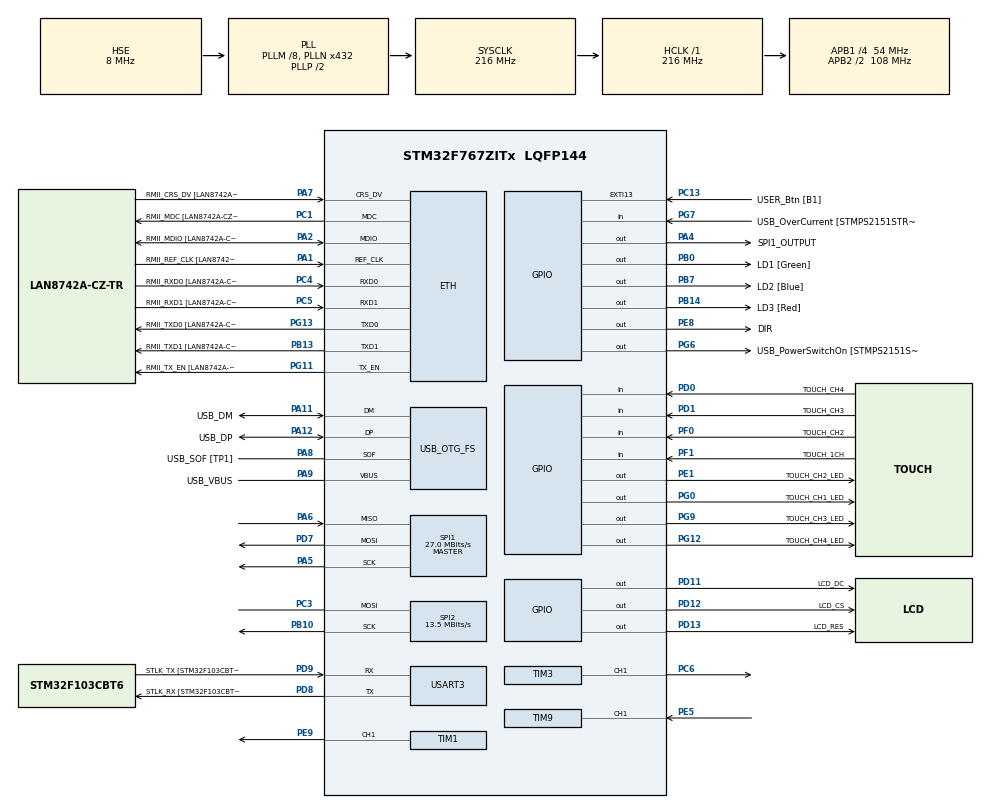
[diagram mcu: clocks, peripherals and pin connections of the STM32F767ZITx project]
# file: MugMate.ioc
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Dma.Request0=USART3_RX
Dma.Request1=SPI2_TX
Dma.SPI2_TX.1.Direction=DMA_MEMORY_TO_PERIPH
Dma.SPI2_TX.1.FIFOMode=DMA_FIFOMODE_DISABLE
Dma.SPI2_TX.1.Instance=DMA1_Stream4
Dma.SPI2_TX.1.MemDataAlignment=DMA_MDATAALIGN_BYTE
Dma.SPI2_TX.1.MemInc=DMA_MINC_ENABLE
Dma.SPI2_TX.1.Mode=DMA_NORMAL
Dma.SPI2_TX.1.PeriphDataAlignment=DMA_PDATAALIGN_BYTE
Dma.SPI2_TX.1.PeriphInc=DMA_PINC_DISABLE
Dma.SPI2_TX.1.Priority=DMA_PRIORITY_LOW
Dma.USART3_RX.0.Direction=DMA_PERIPH_TO_MEMORY
Dma.USART3_RX.0.FIFOMode=DMA_FIFOMODE_DISABLE
Dma.USART3_RX.0.Instance=DMA1_Stream1
Dma.USART3_RX.0.MemDataAlignment=DMA_MDATAALIGN_BYTE
Dma.USART3_RX.0.MemInc=DMA_MINC_ENABLE
Dma.USART3_RX.0.Mode=DMA_CIRCULAR
Dma.USART3_RX.0.PeriphDataAlignment=DMA_PDATAALIGN_BYTE
Dma.USART3_RX.0.PeriphInc=DMA_PINC_DISABLE
Dma.USART3_RX.0.Priority=DMA_PRIORITY_MEDIUM
ETH.MediaInterface=HAL_ETH_RMII_MODE
ETH.PHY_Name=LAN8742A_PHY_ADDRESS
ETH.PHY_Value=0
ETH.PhyAddress=0
Mcu.Family=STM32F7
Mcu.Name=STM32F767ZITx
Mcu.Package=LQFP144
NVIC.DMA1_Stream1_IRQn=true\:0\:0\:false\:false\:true\:false\:true\:true
NVIC.DMA1_Stream4_IRQn=true\:0\:0\:false\:false\:true\:false\:true\:true
NVIC.PriorityGroup=NVIC_PRIORITYGROUP_4
NVIC.TIM1_BRK_TIM9_IRQn=true\:0\:0\:false\:false\:true\:true\:true\:true
PA1.GPIO_Label=RMII_REF_CLK [LAN8742A-CZ-TR_REFCLK0]
PA1.Mode=RMII
PA1.Signal=ETH_REF_CLK
PA10.GPIO_Label=USB_ID
PA10.Signal=USB_OTG_FS_ID
PA11.GPIO_Label=USB_DM
PA11.Mode=Device_Only
PA11.Signal=USB_OTG_FS_DM
PA12.GPIO_Label=USB_DP
PA12.Mode=Device_Only
PA12.Signal=USB_OTG_FS_DP
PA13.GPIO_Label=TMS
PA13.Mode=Serial_Wire
PA13.Signal=SYS_JTMS-SWDIO
PA14.GPIO_Label=TCK
PA14.Mode=Serial_Wire
PA14.Signal=SYS_JTCK-SWCLK
PA2.GPIO_Label=RMII_MDIO [LAN8742A-CZ-TR_MDIO]
PA2.Mode=RMII
PA2.Signal=ETH_MDIO
PA4.GPIO_Label=SPI1_OUTPUT
PA4.PinState=GPIO_PIN_SET
PA4.Signal=GPIO_Output
PA5.Mode=Full_Duplex_Master
PA5.Signal=SPI1_SCK
PA6.Mode=Full_Duplex_Master
PA6.Signal=SPI1_MISO
PA7.GPIO_Label=RMII_CRS_DV [LAN8742A-CZ-TR_CRS_DV]
PA7.Mode=RMII
PA7.Signal=ETH_CRS_DV
PA8.GPIO_Label=USB_SOF [TP1]
PA8.Mode=Activate_SOF_FS
PA8.Signal=USB_OTG_FS_SOF
PA9.GPIO_Label=USB_VBUS
PA9.Mode=Activate_VBUS
PA9.Signal=USB_OTG_FS_VBUS
PB0.GPIO_Label=LD1 [Green]
PB0.Signal=GPIO_Output
PB10.Mode=Simplex_Bidirectional_Master
PB10.Signal=SPI2_SCK
PB13.GPIO_Label=RMII_TXD1 [LAN8742A-CZ-TR_TXD1]
PB13.Mode=RMII
PB13.Signal=ETH_TXD1
PB14.GPIO_Label=LD3 [Red]
PB14.Signal=GPIO_Output
PB3.GPIO_Label=SWO
PB3.Signal=SYS_JTDO-SWO
PB7.GPIO_Label=LD2 [Blue]
PB7.Signal=GPIO_Output
PC1.GPIO_Label=RMII_MDC [LAN8742A-CZ-TR_MDC]
PC1.Mode=RMII
PC1.Signal=ETH_MDC
PC13.GPIO_Label=USER_Btn [B1]
PC13.Signal=GPXTI13
PC14/OSC32_IN.Mode=LSE-External-Oscillator
PC14/OSC32_IN.Signal=RCC_OSC32_IN
PC15/OSC32_OUT.Mode=LSE-External-Oscillator
PC15/OSC32_OUT.Signal=RCC_OSC32_OUT
PC3.GPIO_PuPd=GPIO_PULLUP
PC3.Mode=Simplex_Bidirectional_Master
PC3.Signal=SPI2_MOSI
PC4.GPIO_Label=RMII_RXD0 [LAN8742A-CZ-TR_RXD0]
PC4.Mode=RMII
PC4.Signal=ETH_RXD0
PC5.GPIO_Label=RMII_RXD1 [LAN8742A-CZ-TR_RXD1]
PC5.Mode=RMII
PC5.Signal=ETH_RXD1
PC6.Signal=S_TIM3_CH1
PD0.GPIO_Label=TOUCH_CH4
PD0.GPIO_PuPd=GPIO_PULLUP
PD0.Signal=GPIO_Input
PD1.GPIO_Label=TOUCH_CH3
PD1.GPIO_PuPd=GPIO_PULLUP
PD1.Signal=GPIO_Input
PD11.GPIO_Label=LCD_DC
PD11.GPIO_PuPd=GPIO_NOPULL
PD11.GPIO_Speed=GPIO_SPEED_FREQ_HIGH
PD11.Signal=GPIO_Output
PD12.GPIO_Label=LCD_CS
PD12.GPIO_Speed=GPIO_SPEED_FREQ_HIGH
PD12.Signal=GPIO_Output
PD13.GPIO_Label=LCD_RES
PD13.GPIO_Speed=GPIO_SPEED_FREQ_HIGH
PD13.Signal=GPIO_Output
PD7.Mode=Full_Duplex_Master
PD7.Signal=SPI1_MOSI
PD8.GPIO_Label=STLK_RX [STM32F103CBT6_PA3]
PD8.Mode=Asynchronous
PD8.Signal=USART3_TX
PD9.GPIO_Label=STLK_TX [STM32F103CBT6_PA2]
PD9.Mode=Asynchronous
PD9.Signal=USART3_RX
PE1.GPIO_Label=TOUCH_CH2_LED
PE1.Signal=GPIO_Output
PE5.GPIO_ModeDefaultPP=GPIO_MODE_AF_OD
PE5.GPIO_PuPd=GPIO_PULLUP
PE5.Signal=S_TIM9_CH1
PE8.GPIO_Label=DIR
PE8.Signal=GPIO_Output
PE9.GPIO_ModeDefaultPP=GPIO_MODE_AF_PP
PE9.GPIO_PuPd=GPIO_NOPULL
PE9.Signal=S_TIM1_CH1
PF0.GPIO_Label=TOUCH_CH2
PF0.GPIO_PuPd=GPIO_PULLUP
PF0.Signal=GPIO_Input
PF1.GPIO_Label=TOUCH_1CH
PF1.GPIO_PuPd=GPIO_PULLUP
PF1.Signal=GPIO_Input
PG0.GPIO_Label=TOUCH_CH1_LED
PG0.Signal=GPIO_Output
PG11.GPIO_Label=RMII_TX_EN [LAN8742A-CZ-TR_TXEN]
PG11.Mode=RMII
PG11.Signal=ETH_TX_EN
PG12.GPIO_Label=TOUCH_CH4_LED
PG12.Signal=GPIO_Output
PG13.GPIO_Label=RMII_TXD0 [LAN8742A-CZ-TR_TXD0]
PG13.Mode=RMII
PG13.Signal=ETH_TXD0
PG6.GPIO_Label=USB_PowerSwitchOn [STMPS2151STR_EN]
PG6.Signal=GPIO_Output
PG7.GPIO_Label=USB_OverCurrent [STMPS2151STR_FAULT]
PG7.Signal=GPIO_Input
PG9.GPIO_Label=TOUCH_CH3_LED
PG9.Signal=GPIO_Output
PH0/OSC_IN.GPIO_Label=MCO [STM32F103CBT6_PA8]
PH0/OSC_IN.Mode=HSE-External-Clock-Source
PH0/OSC_IN.Signal=RCC_OSC_IN
PH1/OSC_OUT.Mode=HSE-External-Clock-Source
PH1/OSC_OUT.Signal=RCC_OSC_OUT
ProjectManager.HeapSize=0x200
ProjectManager.StackSize=0x400
ProjectManager.TargetToolchain=STM32CubeIDE
RCC.48MHZClocksFreq_Value=24000000
RCC.AHBFreq_Value=216000000
RCC.APB1CLKDivider=RCC_HCLK_DIV4
RCC.APB1Freq_Value=54000000
RCC.APB1TimFreq_Value=108000000
RCC.APB2CLKDivider=RCC_HCLK_DIV2
RCC.APB2Freq_Value=108000000
RCC.APB2TimFreq_Value=216000000
RCC.CortexFreq_Value=216000000
RCC.HCLKFreq_Value=216000000
RCC.HSE_VALUE=8000000
RCC.HSI_VALUE=16000000
RCC.PLLM=8
RCC.PLLMUL=RCC_PLL_MUL9
RCC.PLLN=432
RCC.PLLQ=9
RCC.PRESCALERUSB=RCC_USBCLKSOURCE_PLL_DIV1_5
RCC.SYSCLKFreq_VALUE=216000000
RCC.SYSCLKSource=RCC_SYSCLKSOURCE_PLLCLK
RCC.SYSCLKSourceVirtual=RCC_SYSCLKSOURCE_PLLCLK
RCC.USBFreq_Value=48000000
RCC.VCOOutputFreq_Value=432000000
SH.S_TIM1_CH1.0=TIM1_CH1,PWM Generation1 CH1
SH.S_TIM3_CH1.0=TIM3_CH1,PWM Generation1 CH1
SH.S_TIM9_CH1.0=TIM9_CH1,Input_Capture1_from_TI1
SPI1.BaudRatePrescaler=SPI_BAUDRATEPRESCALER_4
SPI1.CalculateBaudRate=27.0 MBits/s
SPI1.DataSize=SPI_DATASIZE_8BIT
SPI1.Direction=SPI_DIRECTION_2LINES
SPI1.Mode=SPI_MODE_MASTER
SPI1.VirtualType=VM_MASTER
SPI2.BaudRatePrescaler=SPI_BAUDRATEPRESCALER_4
SPI2.CLKPhase=SPI_PHASE_1EDGE
SPI2.CLKPolarity=SPI_POLARITY_LOW
SPI2.CalculateBaudRate=13.5 MBits/s
SPI2.DataSize=SPI_DATASIZE_8BIT
SPI2.Direction=SPI_DIRECTION_1LINE
SPI2.Mode=SPI_MODE_MASTER
SPI2.VirtualType=VM_MASTER
TIM1.Channel-PWM\ Generation1\ CH1=TIM_CHANNEL_1
TIM1.Period=999
TIM1.Prescaler=10
TIM3.AutoReloadPreload=TIM_AUTORELOAD_PRELOAD_ENABLE
TIM3.Channel-PWM\ Generation1\ CH1=TIM_CHANNEL_1
TIM3.Period=999
TIM3.Prescaler=2159
TIM9.AutoReloadPreload=TIM_AUTORELOAD_PRELOAD_ENABLE
TIM9.Channel-Input_Capture1_from_TI1=TIM_CHANNEL_1
TIM9.ICPolarity_CH1=TIM_INPUTCHANNELPOLARITY_FALLING
TIM9.Period=65535
TIM9.Prescaler=21599
USART3.VirtualMode-Asynchronous=VM_ASYNC
USB_OTG_FS.VirtualMode=Device_Only
VP_TIM1_VS_ClockSourceINT.Mode=Internal
VP_TIM3_VS_ClockSourceINT.Mode=Internal
board=NUCLEO-F767ZI

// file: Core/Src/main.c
/* USER CODE BEGIN Header */
/**
  ******************************************************************************
  * @file           : main.c
  * @brief          : Main program body
  ******************************************************************************
  * @attention
  *
  * Copyright (c) 2025 STMicroelectronics.
  * All rights reserved.
  *
  * This software is licensed under terms that can be found in the LICENSE file
  * in the root directory of this software component.
  * If no LICENSE file comes with this software, it is provided AS-IS.
  *
  ******************************************************************************
  */
/* USER CODE END Header */
#include "main.h"
#include "string.h"

/* USER CODE BEGIN Includes */
#include "ap.h"
/* USER CODE END Includes */

#if defined ( __ICCARM__ ) /*!< IAR Compiler */
#pragma location=0x2007c000
ETH_DMADescTypeDef  DMARxDscrTab[ETH_RX_DESC_CNT]; /* Ethernet Rx DMA Descriptors */
#pragma location=0x2007c0a0
ETH_DMADescTypeDef  DMATxDscrTab[ETH_TX_DESC_CNT]; /* Ethernet Tx DMA Descriptors */

#elif defined ( __CC_ARM )  /* MDK ARM Compiler */

__attribute__((at(0x2007c000))) ETH_DMADescTypeDef  DMARxDscrTab[ETH_RX_DESC_CNT]; /* Ethernet Rx DMA Descriptors */
__attribute__((at(0x2007c0a0))) ETH_DMADescTypeDef  DMATxDscrTab[ETH_TX_DESC_CNT]; /* Ethernet Tx DMA Descriptors */

#elif defined ( __GNUC__ ) /* GNU Compiler */

ETH_DMADescTypeDef DMARxDscrTab[ETH_RX_DESC_CNT] __attribute__((section(".RxDecripSection"))); /* Ethernet Rx DMA Descriptors */
ETH_DMADescTypeDef DMATxDscrTab[ETH_TX_DESC_CNT] __attribute__((section(".TxDecripSection")));   /* Ethernet Tx DMA Descriptors */
#endif

ETH_TxPacketConfig TxConfig;

ETH_HandleTypeDef heth;

SPI_HandleTypeDef hspi1;
SPI_HandleTypeDef hspi2;
DMA_HandleTypeDef hdma_spi2_tx;

TIM_HandleTypeDef htim1;
TIM_HandleTypeDef htim3;
TIM_HandleTypeDef htim9;

UART_HandleTypeDef huart3;
DMA_HandleTypeDef hdma_usart3_rx;

PCD_HandleTypeDef hpcd_USB_OTG_FS;

void SystemClock_Config(void);
static void MX_GPIO_Init(void);
static void MX_DMA_Init(void);
static void MX_ETH_Init(void);
static void MX_USART3_UART_Init(void);
static void MX_USB_OTG_FS_PCD_Init(void);
static void MX_SPI1_Init(void);
static void MX_TIM1_Init(void);
static void MX_SPI2_Init(void);
static void MX_TIM3_Init(void);
static void MX_TIM9_Init(void);

int main(void)
{

  /* MCU Configuration--------------------------------------------------------*/

  /* Reset of all peripherals, Initializes the Flash interface and the Systick. */
  HAL_Init();

  /* Configure the system clock */
  SystemClock_Config();

  /* Initialize all configured peripherals */
  MX_GPIO_Init();
  MX_DMA_Init();
  MX_ETH_Init();
  MX_USART3_UART_Init();
  MX_USB_OTG_FS_PCD_Init();
  MX_SPI1_Init();
  MX_TIM1_Init();
  MX_SPI2_Init();
  MX_TIM3_Init();
  MX_TIM9_Init();
  /* USER CODE BEGIN 2 */
  apInit();
  apMain();
  /* USER CODE END 2 */

  /* Infinite loop */
  while (1)
  {

    /* USER CODE BEGIN 3 */
  	apMain();
  }
  /* USER CODE END 3 */
}

void SystemClock_Config(void)
{
  RCC_OscInitTypeDef RCC_OscInitStruct = {0};
  RCC_ClkInitTypeDef RCC_ClkInitStruct = {0};

  /** Configure LSE Drive Capability
  */
  HAL_PWR_EnableBkUpAccess();

  /** Configure the main internal regulator output voltage
  */
  __HAL_RCC_PWR_CLK_ENABLE();
  __HAL_PWR_VOLTAGESCALING_CONFIG(PWR_REGULATOR_VOLTAGE_SCALE1);

  /** Initializes the RCC Oscillators according to the specified parameters
  * in the RCC_OscInitTypeDef structure.
  */
  RCC_OscInitStruct.OscillatorType = RCC_OSCILLATORTYPE_HSE;
  RCC_OscInitStruct.HSEState = RCC_HSE_BYPASS;
  RCC_OscInitStruct.PLL.PLLState = RCC_PLL_ON;
  RCC_OscInitStruct.PLL.PLLSource = RCC_PLLSOURCE_HSE;
  RCC_OscInitStruct.PLL.PLLM = 8;
  RCC_OscInitStruct.PLL.PLLN = 432;
  RCC_OscInitStruct.PLL.PLLP = RCC_PLLP_DIV2;
  RCC_OscInitStruct.PLL.PLLQ = 9;
  RCC_OscInitStruct.PLL.PLLR = 2;
  if (HAL_RCC_OscConfig(&RCC_OscInitStruct) != HAL_OK)
  {
    Error_Handler();
  }

  /** Activate the Over-Drive mode
  */
  if (HAL_PWREx_EnableOverDrive() != HAL_OK)
  {
    Error_Handler();
  }

  /** Initializes the CPU, AHB and APB buses clocks
  */
  RCC_ClkInitStruct.ClockType = RCC_CLOCKTYPE_HCLK|RCC_CLOCKTYPE_SYSCLK
                              |RCC_CLOCKTYPE_PCLK1|RCC_CLOCKTYPE_PCLK2;
  RCC_ClkInitStruct.SYSCLKSource = RCC_SYSCLKSOURCE_PLLCLK;
  RCC_ClkInitStruct.AHBCLKDivider = RCC_SYSCLK_DIV1;
  RCC_ClkInitStruct.APB1CLKDivider = RCC_HCLK_DIV4;
  RCC_ClkInitStruct.APB2CLKDivider = RCC_HCLK_DIV2;

  if (HAL_RCC_ClockConfig(&RCC_ClkInitStruct, FLASH_LATENCY_7) != HAL_OK)
  {
    Error_Handler();
  }
}

static void MX_ETH_Init(void)
{

   static uint8_t MACAddr[6];

  heth.Instance = ETH;
  MACAddr[0] = 0x00;
  MACAddr[1] = 0x80;
  MACAddr[2] = 0xE1;
  MACAddr[3] = 0x00;
  MACAddr[4] = 0x00;
  MACAddr[5] = 0x00;
  heth.Init.MACAddr = &MACAddr[0];
  heth.Init.MediaInterface = HAL_ETH_RMII_MODE;
  heth.Init.TxDesc = DMATxDscrTab;
  heth.Init.RxDesc = DMARxDscrTab;
  heth.Init.RxBuffLen = 1524;

  if (HAL_ETH_Init(&heth) != HAL_OK)
  {
    Error_Handler();
  }

  memset(&TxConfig, 0 , sizeof(ETH_TxPacketConfig));
  TxConfig.Attributes = ETH_TX_PACKETS_FEATURES_CSUM | ETH_TX_PACKETS_FEATURES_CRCPAD;
  TxConfig.ChecksumCtrl = ETH_CHECKSUM_IPHDR_PAYLOAD_INSERT_PHDR_CALC;
  TxConfig.CRCPadCtrl = ETH_CRC_PAD_INSERT;

}

static void MX_SPI1_Init(void)
{

  /* SPI1 parameter configuration*/
  hspi1.Instance = SPI1;
  hspi1.Init.Mode = SPI_MODE_MASTER;
  hspi1.Init.Direction = SPI_DIRECTION_2LINES;
  hspi1.Init.DataSize = SPI_DATASIZE_8BIT;
  hspi1.Init.CLKPolarity = SPI_POLARITY_LOW;
  hspi1.Init.CLKPhase = SPI_PHASE_1EDGE;
  hspi1.Init.NSS = SPI_NSS_SOFT;
  hspi1.Init.BaudRatePrescaler = SPI_BAUDRATEPRESCALER_4;
  hspi1.Init.FirstBit = SPI_FIRSTBIT_MSB;
  hspi1.Init.TIMode = SPI_TIMODE_DISABLE;
  hspi1.Init.CRCCalculation = SPI_CRCCALCULATION_DISABLE;
  hspi1.Init.CRCPolynomial = 7;
  hspi1.Init.CRCLength = SPI_CRC_LENGTH_DATASIZE;
  hspi1.Init.NSSPMode = SPI_NSS_PULSE_ENABLE;
  if (HAL_SPI_Init(&hspi1) != HAL_OK)
  {
    Error_Handler();
  }

}

static void MX_SPI2_Init(void)
{

  /* SPI2 parameter configuration*/
  hspi2.Instance = SPI2;
  hspi2.Init.Mode = SPI_MODE_MASTER;
  hspi2.Init.Direction = SPI_DIRECTION_1LINE;
  hspi2.Init.DataSize = SPI_DATASIZE_8BIT;
  hspi2.Init.CLKPolarity = SPI_POLARITY_LOW;
  hspi2.Init.CLKPhase = SPI_PHASE_1EDGE;
  hspi2.Init.NSS = SPI_NSS_SOFT;
  hspi2.Init.BaudRatePrescaler = SPI_BAUDRATEPRESCALER_4;
  hspi2.Init.FirstBit = SPI_FIRSTBIT_MSB;
  hspi2.Init.TIMode = SPI_TIMODE_DISABLE;
  hspi2.Init.CRCCalculation = SPI_CRCCALCULATION_DISABLE;
  hspi2.Init.CRCPolynomial = 7;
  hspi2.Init.CRCLength = SPI_CRC_LENGTH_DATASIZE;
  hspi2.Init.NSSPMode = SPI_NSS_PULSE_ENABLE;
  if (HAL_SPI_Init(&hspi2) != HAL_OK)
  {
    Error_Handler();
  }

}

static void MX_TIM1_Init(void)
{

  TIM_ClockConfigTypeDef sClockSourceConfig = {0};
  TIM_MasterConfigTypeDef sMasterConfig = {0};
  TIM_OC_InitTypeDef sConfigOC = {0};
  TIM_BreakDeadTimeConfigTypeDef sBreakDeadTimeConfig = {0};

  htim1.Instance = TIM1;
  htim1.Init.Prescaler = 10;
  htim1.Init.CounterMode = TIM_COUNTERMODE_UP;
  htim1.Init.Period = 999;
  htim1.Init.ClockDivision = TIM_CLOCKDIVISION_DIV1;
  htim1.Init.RepetitionCounter = 0;
  htim1.Init.AutoReloadPreload = TIM_AUTORELOAD_PRELOAD_DISABLE;
  if (HAL_TIM_Base_Init(&htim1) != HAL_OK)
  {
    Error_Handler();
  }
  sClockSourceConfig.ClockSource = TIM_CLOCKSOURCE_INTERNAL;
  if (HAL_TIM_ConfigClockSource(&htim1, &sClockSourceConfig) != HAL_OK)
  {
    Error_Handler();
  }
  if (HAL_TIM_PWM_Init(&htim1) != HAL_OK)
  {
    Error_Handler();
  }
  sMasterConfig.MasterOutputTrigger = TIM_TRGO_RESET;
  sMasterConfig.MasterOutputTrigger2 = TIM_TRGO2_RESET;
  sMasterConfig.MasterSlaveMode = TIM_MASTERSLAVEMODE_DISABLE;
  if (HAL_TIMEx_MasterConfigSynchronization(&htim1, &sMasterConfig) != HAL_OK)
  {
    Error_Handler();
  }
  sConfigOC.OCMode = TIM_OCMODE_PWM1;
  sConfigOC.Pulse = 0;
  sConfigOC.OCPolarity = TIM_OCPOLARITY_HIGH;
  sConfigOC.OCNPolarity = TIM_OCNPOLARITY_HIGH;
  sConfigOC.OCFastMode = TIM_OCFAST_DISABLE;
  sConfigOC.OCIdleState = TIM_OCIDLESTATE_RESET;
  sConfigOC.OCNIdleState = TIM_OCNIDLESTATE_RESET;
  if (HAL_TIM_PWM_ConfigChannel(&htim1, &sConfigOC, TIM_CHANNEL_1) != HAL_OK)
  {
    Error_Handler();
  }
  sBreakDeadTimeConfig.OffStateRunMode = TIM_OSSR_DISABLE;
  sBreakDeadTimeConfig.OffStateIDLEMode = TIM_OSSI_DISABLE;
  sBreakDeadTimeConfig.LockLevel = TIM_LOCKLEVEL_OFF;
  sBreakDeadTimeConfig.DeadTime = 0;
  sBreakDeadTimeConfig.BreakState = TIM_BREAK_DISABLE;
  sBreakDeadTimeConfig.BreakPolarity = TIM_BREAKPOLARITY_HIGH;
  sBreakDeadTimeConfig.BreakFilter = 0;
  sBreakDeadTimeConfig.Break2State = TIM_BREAK2_DISABLE;
  sBreakDeadTimeConfig.Break2Polarity = TIM_BREAK2POLARITY_HIGH;
  sBreakDeadTimeConfig.Break2Filter = 0;
  sBreakDeadTimeConfig.AutomaticOutput = TIM_AUTOMATICOUTPUT_DISABLE;
  if (HAL_TIMEx_ConfigBreakDeadTime(&htim1, &sBreakDeadTimeConfig) != HAL_OK)
  {
    Error_Handler();
  }
  HAL_TIM_MspPostInit(&htim1);

}

static void MX_TIM3_Init(void)
{

  TIM_ClockConfigTypeDef sClockSourceConfig = {0};
  TIM_MasterConfigTypeDef sMasterConfig = {0};
  TIM_OC_InitTypeDef sConfigOC = {0};

  htim3.Instance = TIM3;
  htim3.Init.Prescaler = 2159;
  htim3.Init.CounterMode = TIM_COUNTERMODE_UP;
  htim3.Init.Period = 999;
  htim3.Init.ClockDivision = TIM_CLOCKDIVISION_DIV1;
  htim3.Init.AutoReloadPreload = TIM_AUTORELOAD_PRELOAD_ENABLE;
  if (HAL_TIM_Base_Init(&htim3) != HAL_OK)
  {
    Error_Handler();
  }
  sClockSourceConfig.ClockSource = TIM_CLOCKSOURCE_INTERNAL;
  if (HAL_TIM_ConfigClockSource(&htim3, &sClockSourceConfig) != HAL_OK)
  {
    Error_Handler();
  }
  if (HAL_TIM_PWM_Init(&htim3) != HAL_OK)
  {
    Error_Handler();
  }
  sMasterConfig.MasterOutputTrigger = TIM_TRGO_RESET;
  sMasterConfig.MasterSlaveMode = TIM_MASTERSLAVEMODE_DISABLE;
  if (HAL_TIMEx_MasterConfigSynchronization(&htim3, &sMasterConfig) != HAL_OK)
  {
    Error_Handler();
  }
  sConfigOC.OCMode = TIM_OCMODE_PWM1;
  sConfigOC.Pulse = 0;
  sConfigOC.OCPolarity = TIM_OCPOLARITY_HIGH;
  sConfigOC.OCFastMode = TIM_OCFAST_DISABLE;
  if (HAL_TIM_PWM_ConfigChannel(&htim3, &sConfigOC, TIM_CHANNEL_1) != HAL_OK)
  {
    Error_Handler();
  }
  HAL_TIM_MspPostInit(&htim3);

}

static void MX_TIM9_Init(void)
{

  TIM_IC_InitTypeDef sConfigIC = {0};

  htim9.Instance = TIM9;
  htim9.Init.Prescaler = 21599;
  htim9.Init.CounterMode = TIM_COUNTERMODE_UP;
  htim9.Init.Period = 65535;
  htim9.Init.ClockDivision = TIM_CLOCKDIVISION_DIV1;
  htim9.Init.AutoReloadPreload = TIM_AUTORELOAD_PRELOAD_ENABLE;
  if (HAL_TIM_IC_Init(&htim9) != HAL_OK)
  {
    Error_Handler();
  }
  sConfigIC.ICPolarity = TIM_INPUTCHANNELPOLARITY_FALLING;
  sConfigIC.ICSelection = TIM_ICSELECTION_DIRECTTI;
  sConfigIC.ICPrescaler = TIM_ICPSC_DIV1;
  sConfigIC.ICFilter = 0;
  if (HAL_TIM_IC_ConfigChannel(&htim9, &sConfigIC, TIM_CHANNEL_1) != HAL_OK)
  {
    Error_Handler();
  }

}

static void MX_USART3_UART_Init(void)
{

  huart3.Instance = USART3;
  huart3.Init.BaudRate = 115200;
  huart3.Init.WordLength = UART_WORDLENGTH_8B;
  huart3.Init.StopBits = UART_STOPBITS_1;
  huart3.Init.Parity = UART_PARITY_NONE;
  huart3.Init.Mode = UART_MODE_TX_RX;
  huart3.Init.HwFlowCtl = UART_HWCONTROL_NONE;
  huart3.Init.OverSampling = UART_OVERSAMPLING_16;
  huart3.Init.OneBitSampling = UART_ONE_BIT_SAMPLE_DISABLE;
  huart3.AdvancedInit.AdvFeatureInit = UART_ADVFEATURE_NO_INIT;
  if (HAL_UART_Init(&huart3) != HAL_OK)
  {
    Error_Handler();
  }

}

static void MX_USB_OTG_FS_PCD_Init(void)
{

  hpcd_USB_OTG_FS.Instance = USB_OTG_FS;
  hpcd_USB_OTG_FS.Init.dev_endpoints = 6;
  hpcd_USB_OTG_FS.Init.speed = PCD_SPEED_FULL;
  hpcd_USB_OTG_FS.Init.dma_enable = DISABLE;
  hpcd_USB_OTG_FS.Init.phy_itface = PCD_PHY_EMBEDDED;
  hpcd_USB_OTG_FS.Init.Sof_enable = ENABLE;
  hpcd_USB_OTG_FS.Init.low_power_enable = DISABLE;
  hpcd_USB_OTG_FS.Init.lpm_enable = DISABLE;
  hpcd_USB_OTG_FS.Init.vbus_sensing_enable = ENABLE;
  hpcd_USB_OTG_FS.Init.use_dedicated_ep1 = DISABLE;
  if (HAL_PCD_Init(&hpcd_USB_OTG_FS) != HAL_OK)
  {
    Error_Handler();
  }

}

static void MX_DMA_Init(void)
{

  /* DMA controller clock enable */
  __HAL_RCC_DMA1_CLK_ENABLE();

  /* DMA interrupt init */
  /* DMA1_Stream1_IRQn interrupt configuration */
  HAL_NVIC_SetPriority(DMA1_Stream1_IRQn, 0, 0);
  HAL_NVIC_EnableIRQ(DMA1_Stream1_IRQn);
  /* DMA1_Stream4_IRQn interrupt configuration */
  HAL_NVIC_SetPriority(DMA1_Stream4_IRQn, 0, 0);
  HAL_NVIC_EnableIRQ(DMA1_Stream4_IRQn);

}

static void MX_GPIO_Init(void)
{
  GPIO_InitTypeDef GPIO_InitStruct = {0};

  /* GPIO Ports Clock Enable */
  __HAL_RCC_GPIOE_CLK_ENABLE();
  __HAL_RCC_GPIOC_CLK_ENABLE();
  __HAL_RCC_GPIOF_CLK_ENABLE();
  __HAL_RCC_GPIOH_CLK_ENABLE();
  __HAL_RCC_GPIOA_CLK_ENABLE();
  __HAL_RCC_GPIOB_CLK_ENABLE();
  __HAL_RCC_GPIOG_CLK_ENABLE();
  __HAL_RCC_GPIOD_CLK_ENABLE();

  /*Configure GPIO pin Output Level */
  HAL_GPIO_WritePin(SPI1_OUTPUT_GPIO_Port, SPI1_OUTPUT_Pin, GPIO_PIN_SET);

  /*Configure GPIO pin Output Level */
  HAL_GPIO_WritePin(GPIOB, LD1_Pin|LD3_Pin|LD2_Pin, GPIO_PIN_RESET);

  /*Configure GPIO pin Output Level */
  HAL_GPIO_WritePin(GPIOG, TOUCH_CH1_LED_Pin|USB_PowerSwitchOn_Pin|TOUCH_CH3_LED_Pin|TOUCH_CH4_LED_Pin, GPIO_PIN_RESET);

  /*Configure GPIO pin Output Level */
  HAL_GPIO_WritePin(GPIOE, DIR_Pin|TOUCH_CH2_LED_Pin, GPIO_PIN_RESET);

  /*Configure GPIO pin Output Level */
  HAL_GPIO_WritePin(GPIOD, LCD_DC_Pin|LCD_CS_Pin|LCD_RES_Pin, GPIO_PIN_RESET);

  /*Configure GPIO pin : USER_Btn_Pin */
  GPIO_InitStruct.Pin = USER_Btn_Pin;
  GPIO_InitStruct.Mode = GPIO_MODE_IT_RISING;
  GPIO_InitStruct.Pull = GPIO_NOPULL;
  HAL_GPIO_Init(USER_Btn_GPIO_Port, &GPIO_InitStruct);

  /*Configure GPIO pins : TOUCH_CH2_Pin TOUCH_1CH_Pin */
  GPIO_InitStruct.Pin = TOUCH_CH2_Pin|TOUCH_1CH_Pin;
  GPIO_InitStruct.Mode = GPIO_MODE_INPUT;
  GPIO_InitStruct.Pull = GPIO_PULLUP;
  HAL_GPIO_Init(GPIOF, &GPIO_InitStruct);

  /*Configure GPIO pin : SPI1_OUTPUT_Pin */
  GPIO_InitStruct.Pin = SPI1_OUTPUT_Pin;
  GPIO_InitStruct.Mode = GPIO_MODE_OUTPUT_PP;
  GPIO_InitStruct.Pull = GPIO_NOPULL;
  GPIO_InitStruct.Speed = GPIO_SPEED_FREQ_LOW;
  HAL_GPIO_Init(SPI1_OUTPUT_GPIO_Port, &GPIO_InitStruct);

  /*Configure GPIO pins : LD1_Pin LD3_Pin LD2_Pin */
  GPIO_InitStruct.Pin = LD1_Pin|LD3_Pin|LD2_Pin;
  GPIO_InitStruct.Mode = GPIO_MODE_OUTPUT_PP;
  GPIO_InitStruct.Pull = GPIO_NOPULL;
  GPIO_InitStruct.Speed = GPIO_SPEED_FREQ_LOW;
  HAL_GPIO_Init(GPIOB, &GPIO_InitStruct);

  /*Configure GPIO pins : TOUCH_CH1_LED_Pin USB_PowerSwitchOn_Pin TOUCH_CH3_LED_Pin TOUCH_CH4_LED_Pin */
  GPIO_InitStruct.Pin = TOUCH_CH1_LED_Pin|USB_PowerSwitchOn_Pin|TOUCH_CH3_LED_Pin|TOUCH_CH4_LED_Pin;
  GPIO_InitStruct.Mode = GPIO_MODE_OUTPUT_PP;
  GPIO_InitStruct.Pull = GPIO_NOPULL;
  GPIO_InitStruct.Speed = GPIO_SPEED_FREQ_LOW;
  HAL_GPIO_Init(GPIOG, &GPIO_InitStruct);

  /*Configure GPIO pins : DIR_Pin TOUCH_CH2_LED_Pin */
  GPIO_InitStruct.Pin = DIR_Pin|TOUCH_CH2_LED_Pin;
  GPIO_InitStruct.Mode = GPIO_MODE_OUTPUT_PP;
  GPIO_InitStruct.Pull = GPIO_NOPULL;
  GPIO_InitStruct.Speed = GPIO_SPEED_FREQ_LOW;
  HAL_GPIO_Init(GPIOE, &GPIO_InitStruct);

  /*Configure GPIO pins : LCD_DC_Pin LCD_CS_Pin LCD_RES_Pin */
  GPIO_InitStruct.Pin = LCD_DC_Pin|LCD_CS_Pin|LCD_RES_Pin;
  GPIO_InitStruct.Mode = GPIO_MODE_OUTPUT_PP;
  GPIO_InitStruct.Pull = GPIO_NOPULL;
  GPIO_InitStruct.Speed = GPIO_SPEED_FREQ_HIGH;
  HAL_GPIO_Init(GPIOD, &GPIO_InitStruct);

  /*Configure GPIO pin : USB_OverCurrent_Pin */
  GPIO_InitStruct.Pin = USB_OverCurrent_Pin;
  GPIO_InitStruct.Mode = GPIO_MODE_INPUT;
  GPIO_InitStruct.Pull = GPIO_NOPULL;
  HAL_GPIO_Init(USB_OverCurrent_GPIO_Port, &GPIO_InitStruct);

  /*Configure GPIO pins : TOUCH_CH4_Pin TOUCH_CH3_Pin */
  GPIO_InitStruct.Pin = TOUCH_CH4_Pin|TOUCH_CH3_Pin;
  GPIO_InitStruct.Mode = GPIO_MODE_INPUT;
  GPIO_InitStruct.Pull = GPIO_PULLUP;
  HAL_GPIO_Init(GPIOD, &GPIO_InitStruct);

}

void Error_Handler(void)
{
  __disable_irq();
  while (1)
  {
  }
}
